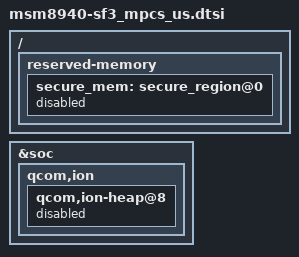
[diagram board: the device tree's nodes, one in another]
/*
 * Copyright (c) 2016, The Linux Foundation. All rights reserved.
 *
 * This program is free software; you can redistribute it and/or modify
 * it under the terms of the GNU General Public License version 2 and
 * only version 2 as published by the Free Software Foundation.
 *
 * This program is distributed in the hope that it will be useful,
 * but WITHOUT ANY WARRANTY; without even the implied warranty of
 * MERCHANTABILITY or FITNESS FOR A PARTICULAR PURPOSE.  See the
 * GNU General Public License for more details.
 */

#include "msm8940-sf3_mpcs_us-pinctrl.dtsi"
#include "msm8940-sf3_mpcs_us-camera.dtsi"
#include "msm8940-sf3_mpcs_us-panel.dtsi"
#include "msm8940-sf3_mpcs_us-sound.dtsi"
#include "msm8940-sf3_mpcs_us-misc.dtsi"
#include "msm8940-sf3_mpcs_us-pm.dtsi"
#include "msm8940-sf3_mpcs_us-touch.dtsi"
#include "msm8940-sf3_mpcs_us-usb.dtsi"
#include "msm8940-sf3_mpcs_us-nfc.dtsi"
#include "msm8940-sf3_mpcs_us-fingerprint.dtsi"
#include "msm8940-sf3_mpcs_us-sensor.dtsi"

/{
	reserved-memory {
		secure_mem: secure_region@0 {
			status = "disabled";
		};
	};
};

&soc {
	qcom,ion {
		qcom,ion-heap@8 { /* CP_MM HEAP  */
			status = "disabled";
		};
	};
};
